AUTOSAR XML (schema 4-2-2)
package /ComponentTypes
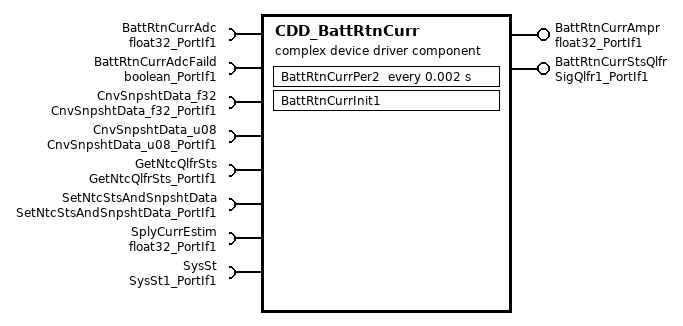
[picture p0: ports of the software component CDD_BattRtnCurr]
  complex device driver sw component type CDD_BattRtnCurr  # Receives ADC samples and converts them to battery return current level expressed in amperes. Current is saturated before outputed.
    provide port BattRtnCurrAmpr: nonqueued-sender-com-spec{data-element=Val, init-value=0}, provided-interface=float32_PortIf1
    provide port BattRtnCurrStsQlfr: nonqueued-sender-com-spec{data-element=Val, init-value=0}, provided-interface=SigQlfr1_PortIf1
    8 x require port:
      BattRtnCurrAdc: nonqueued-receiver-com-spec{data-element=Val, filter=data-filter-type=ALWAYS, init-value=0}, required-interface=float32_PortIf1  # ADC signal used for current mesaurement carried out inside 2ms periodic
      BattRtnCurrAdcFaild: nonqueued-receiver-com-spec{data-element=Logl, filter=data-filter-type=ALWAYS, init-value=0}, required-interface=boolean_PortIf1  # Flag indicating correct ADC sampling operation
      CnvSnpshtData_f32: client-com-spec=Oper, required-interface=CnvSnpshtData_f32_PortIf1  # Convert a float data type to a uint32 data type
      CnvSnpshtData_u08: client-com-spec=Oper, required-interface=CnvSnpshtData_u08_PortIf1  # Convert a uint08 data type to a uint32 data type
      GetNtcQlfrSts: client-com-spec=Oper, required-interface=GetNtcQlfrSts_PortIf1  # None
      SetNtcStsAndSnpshtData: client-com-spec=Oper, required-interface=SetNtcStsAndSnpshtData_PortIf1  # Set NTC Status And Snapshot Data
      SplyCurrEstim: nonqueued-receiver-com-spec{data-element=Val, filter=data-filter-type=ALWAYS, init-value=0}, required-interface=float32_PortIf1  # Supply current estimate calculated from value of electrical input power
      SysSt: nonqueued-receiver-com-spec{data-element=Val, filter=data-filter-type=ALWAYS, init-value=3}, required-interface=SysSt1_PortIf1
    behavior CDD_BattRtnCurr_InternalBehavior
      ar-typed-per-instance-memorys:
        data BattCurrEstimDifLpFil: sw-calibration-access=READ-ONLY, type=FilLpRec1  # Low pass filter used for
        data dBattRtnCurrBfrSatn: sw-calibration-access=READ-ONLY, type=float32
      init event CDD_BattRtnCurr_InitEvent: start-on-event=BattRtnCurrInit1
      timing event TMT_BattRtnCurrPer2: start-on-event=BattRtnCurrPer2, period=0.002
      port-api-options:
        enable-take-address=false, error-handling=NO-TRANSFORMER-ERROR-HANDLING, indirect-api=false, port=BattRtnCurrAdc
        enable-take-address=false, error-handling=NO-TRANSFORMER-ERROR-HANDLING, indirect-api=false, port=BattRtnCurrAdcFaild
        enable-take-address=false, error-handling=NO-TRANSFORMER-ERROR-HANDLING, indirect-api=false, port=BattRtnCurrAmpr
        enable-take-address=false, error-handling=NO-TRANSFORMER-ERROR-HANDLING, indirect-api=false, port=BattRtnCurrStsQlfr
        enable-take-address=false, error-handling=NO-TRANSFORMER-ERROR-HANDLING, indirect-api=false, port=SplyCurrEstim
        enable-take-address=false, error-handling=NO-TRANSFORMER-ERROR-HANDLING, indirect-api=false, port=SysSt
      runnable BattRtnCurrInit1  # RTE init function
      runnable BattRtnCurrPer2  # Battery Return Current measurement periodic execution and NTC update carried out inside 2ms periodic
        data-receive-point-by-arguments:
          4 x access:
            REC_BattRtnCurrAdc_Val: accessed-variable=BattRtnCurrAdc.Val
            REC_BattRtnCurrAdcFaild_Logl: accessed-variable=BattRtnCurrAdcFaild.Logl
            REC_SplyCurrEstim_Val: accessed-variable=SplyCurrEstim.Val
            REC_SysSt_Val: accessed-variable=SysSt.Val
        data-send-points:
          access SEND_BattRtnCurrAmpr_Val: accessed-variable=BattRtnCurrAmpr.Val
          access SEND_BattRtnCurrStsQlfr_Val: accessed-variable=BattRtnCurrStsQlfr.Val
        4 x sync call, all with timeout=0:
          SC_CnvSnpshtData_f32_Oper: operation=CnvSnpshtData_f32.Oper
          SC_CnvSnpshtData_u08_Oper: operation=CnvSnpshtData_u08.Oper
          SC_GetNtcQlfrSts_Oper: operation=GetNtcQlfrSts.Oper
          SC_SetNtcStsAndSnpshtData_Oper: operation=SetNtcStsAndSnpshtData.Oper
  swc implementation CDD_BattRtnCurr_Implementation: behavior=CDD_BattRtnCurr_InternalBehavior
    code-descriptors:
      code Default: artifact-descriptors=autosar-engineering-object={short-label=Default, category=SWSRC}
